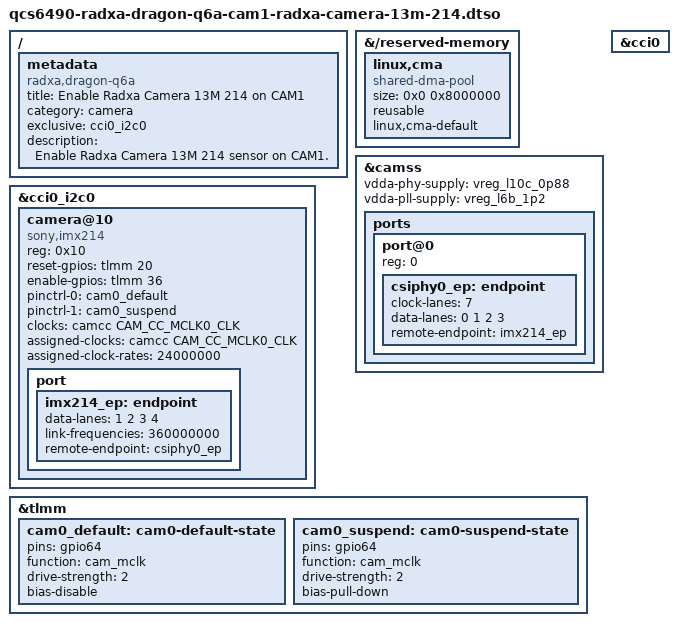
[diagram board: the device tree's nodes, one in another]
// SPDX-License-Identifier: BSD-3-Clause
/*
 * Copyright (c) 2025 Radxa Computer (Shenzhen) Co., Ltd.
 */

/dts-v1/;
/plugin/;

#include <dt-bindings/clock/qcom,camcc-sc7280.h>
#include <dt-bindings/gpio/gpio.h>

/ {
	metadata {
		title = "Enable Radxa Camera 13M 214 on CAM1";
		compatible = "radxa,dragon-q6a";
		category = "camera";
		exclusive = "cci0_i2c0";
		description = "Enable Radxa Camera 13M 214 sensor on CAM1.";
	};
};

&{/reserved-memory} {
	linux,cma {
		compatible = "shared-dma-pool";
		size = <0x0 0x8000000>;
		reusable;
		linux,cma-default;
	};
};

&camss {
	vdda-phy-supply = <&vreg_l10c_0p88>;
	vdda-pll-supply = <&vreg_l6b_1p2>;

	status = "okay";

	ports {
		#address-cells = <1>;
		#size-cells = <0>;

		/* The port index denotes CSIPHY id i.e. csiphy0 */
		port@0 {
			reg = <0>;

			csiphy0_ep: endpoint {
				clock-lanes = <7>;
				data-lanes = <0 1 2 3>;
				remote-endpoint = <&imx214_ep>;
			};
		};
	};
};

&cci0 {
	status = "okay";
};

&cci0_i2c0 {
	#address-cells = <1>;
	#size-cells = <0>;

	camera@10 {
		compatible = "sony,imx214";

		reg = <0x10>;

		reset-gpios = <&tlmm 20 GPIO_ACTIVE_HIGH>;
		enable-gpios = <&tlmm 36 GPIO_ACTIVE_HIGH>;
		pinctrl-names = "default", "suspend";
		pinctrl-0 = <&cam0_default>;
		pinctrl-1 = <&cam0_suspend>;

		clocks = <&camcc CAM_CC_MCLK0_CLK>;
		assigned-clocks = <&camcc CAM_CC_MCLK0_CLK>;
		assigned-clock-rates = <24000000>;

		port {
			imx214_ep: endpoint {
				data-lanes = <1 2 3 4>;
				link-frequencies = /bits/ 64 <360000000>;
				remote-endpoint = <&csiphy0_ep>;
			};
		};
	};
};

&tlmm {
	cam0_default: cam0-default-state {
		pins = "gpio64";
		function = "cam_mclk";
		drive-strength = <2>;
		bias-disable;
	};

	cam0_suspend: cam0-suspend-state {
		pins = "gpio64";
		function = "cam_mclk";
		drive-strength = <2>;
		bias-pull-down;
	};
};
